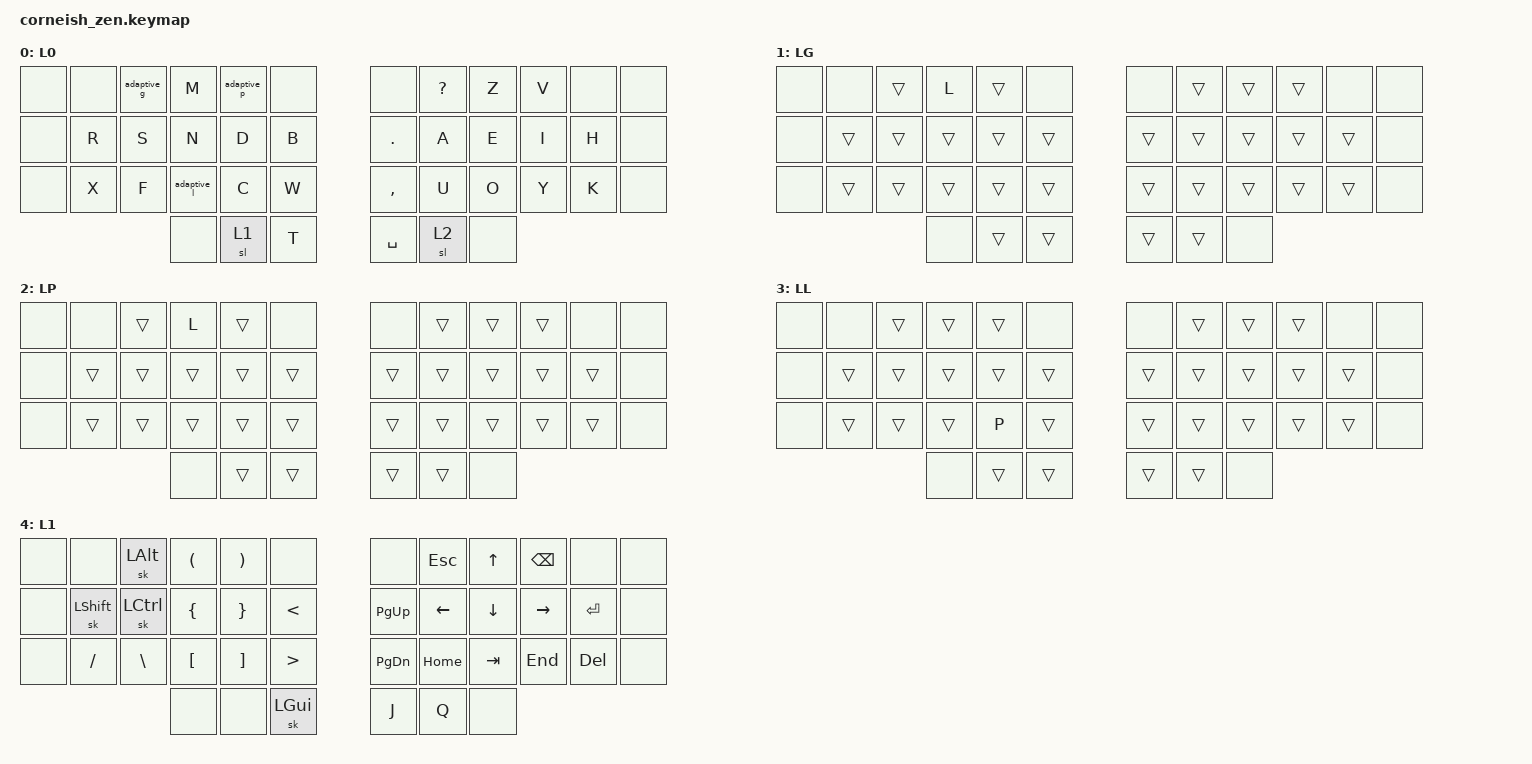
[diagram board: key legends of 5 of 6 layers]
#include <behaviors.dtsi>
#include <dt-bindings/zmk/keys.h>
#include <dt-bindings/zmk/bt.h>
#include <dt-bindings/zmk/outputs.h>

#define U_PST &kp LC(V)
#define U_CPY &kp LC(C)
#define U_CUT &kp LC(X)
#define U_UND &kp LC(Z)
#define U_RDO &kp LC(LS(Z))
#define U_MIC &kp LG(LA(K))

#define L0 0
#define LG 1
#define LP 2
#define LL 3
#define L1 4
#define L2 5

#define HT_1              &http   F1      NUM_1
#define HT_2              &http   F2      NUM_2
#define HT_3              &http   F3      NUM_3
#define HT_4              &http   F4      NUM_4
#define HT_5              &http   F5      NUM_5
#define HT_6              &http   F6      NUM_6
#define HT_7              &http   F7      NUM_7
#define HT_8              &http   F8      NUM_8
#define HT_9              &http   F9      NUM_9
#define HT_10             &http   F10     NUM_0
#define HT_11_AST         &http   F11     KP_ASTERISK
#define HT_12_CUT         &http   F12     LC(X)
#define HT_HASH_AT_SIGN   &http   HASH    AT_SIGN
#define HT_GRAVE_SQT      &http   GRAVE   SQT
#define HT_PERCENT_DOLLAR &http   PERCENT DOLLAR
#define HT_CARET_TILDE    &http   CARET   TILDE

/*
                                L0

      ╭─────┬─────┬─────╮                  ╭─────┬─────┬─────╮
      │  G  │  M  │  P  │                  │  ?  │  Z  │  V  │
╭─────┼─────┼─────┼─────┼─────╮      ╭─────┼─────┼─────┼─────┼─────╮
│  R  │  S  │  N  │  D  │  B  │      │  .  │  A  │  E  │  I  │  H  │
├─────┼─────┼─────┼─────┼─────┤      ├[btc]┼─────┼─────┼─────┼─────┤
│  X  │  F  │  L  │  C  │  W  │      │  ,  │  U  |  O  |  Y  │  K  │
╰─────┴─────┴─────┼─────┼─────┤      ├─────┼─────┼─────┴─────┴─────╯
                  │  L1 │  T  │      │ spc │  L2 │
                  ╰─────┴─────╯      ╰─────┴─────╯

                                 L1

      ╭─────┬─────┬─────╮                  ╭─────┬─────┬─────╮
      │ cut │ cpy │ pst │                  │ esc │  ↑  │ bspc│
╭─────┼─────┼─────┼─────┼─────╮      ╭─────┼─────┼─────┼─────┼─────╮
│ shft│ ctrl│ alt │ gui │ ~ ` │      │ pgup│  ←  │  ↓  │  →  │ ret │
├─────┼─────┼─────┼─────┼─────┤      ├─────┼─────┼─────┼─────┼─────┤
│ / \ │ [ ] │ { } │ ( ) │ < > │      │ pgdn│ home│ tab │ end │ del │
╰─────┴─────┴─────┼─────┼─────┤      ├─────┼─────┼─────┴─────┴─────╯
                  │  L1 │     │      │  J  │  Q  │
                  ╰─────┴─────╯      ╰─────┴─────╯

                                 L2
      ╭─────┬─────┬─────╮                  ╭─────┬─────┬─────╮
 {F10}│{F}7 │{F}8 │{F}9 │                  │  !  │  &  │  |  │
╭──┴──┼─────┼─────┼─────┼─────╮      ╭─────┼─────┼─────┼─────┼─────╮
│  0  │{F}4 │{F}5 │{F}6 │  +  │      │  '  │  "  │  =  │  @  │  ;  │
├─────┼─────┼─────┼─────┼─────┤      ├─────┼─────┼─────┼─────┼─────┤
│  *  │{F}1 │{F}2 │{F}3 │  -  ├{F12} │  ^  │  #  │  $  │  %  │  _  │
╰──┬──┴─────┴─────┼─────┼─────┤      ├─────┼─────┼─────┴─────┴─────╯
 {F11}            │ und │ rdo │      │     │  L2 │
                  ╰─────┴─────╯      ╰─────┴─────╯
*/
/ {
        keymap {
                compatible = "zmk,keymap";
                     L0 {
                        label = "L0";
                        bindings = <
/*                                       ╭───────────────────┬───────────────────┬───────────────────╮                                              ╭───────────────────┬───────────────────┬───────────────────╮                                      */
     &none                  &none              &adaptive_g           &kp M             &adaptive_p          &none                       &none           &kp QUESTION           &kp Z                &kp V               &none            &none
/*                   ╭───────────────────┼───────────────────┼───────────────────┼───────────────────┼───────────────────╮      ╭───────────────────┼───────────────────┼───────────────────┼───────────────────┼───────────────────╮                  */
     &none                  &kp R              &kp S                 &kp N                &kp D             &kp B                      &kp DOT             &kp A               &kp E                &kp I               &kp H            &none
/*                   ├───────────────────┼───────────────────┼───────────────────┼───────────────────┼───────────────────┤      ├───────────────────┼───────────────────┼───────────────────┼───────────────────┼───────────────────┤                  */
     &none                  &kp X              &kp F              &adaptive_l             &kp C             &kp W                     &kp COMMA            &kp U               &kp O                &kp Y               &kp K            &none
/*                   ╰───────────────────┴───────────────────┴───────────────────┼───────────────────┼───────────────────┤      ├───────────────────┼───────────────────┼───────────────────┴───────────────────┴───────────────────╯                  */
                                                                    &none                &sl L1             &kp T                     &kp SPACE            &sl L2           &none
/*                                                                               ╰───────────────────┴───────────────────╯      ╰───────────────────┴───────────────────╯                                                                              */
                             >;
                     };
                     LG {
                        label = "LG";
                        bindings = <
/*                                       ╭───────────────────┬───────────────────┬───────────────────╮                                              ╭───────────────────┬───────────────────┬───────────────────╮                                      */
     &none                  &none               &trans               &kp L              &trans              &none                      &none               &trans               &trans              &trans             &none             &none
/*                   ╭───────────────────┼───────────────────┼───────────────────┼───────────────────┼───────────────────╮      ╭───────────────────┼───────────────────┼───────────────────┼───────────────────┼───────────────────╮                  */
     &none                  &trans              &trans              &trans              &trans              &trans                     &trans              &trans               &trans              &trans             &trans            &none
/*                   ├───────────────────┼───────────────────┼───────────────────┼───────────────────┼───────────────────┤      ├───────────────────┼───────────────────┼───────────────────┼───────────────────┼───────────────────┤                  */
     &none                  &trans              &trans              &trans              &trans              &trans                     &trans              &trans               &trans              &trans             &trans            &none
/*                   ╰───────────────────┴───────────────────┴───────────────────┼───────────────────┼───────────────────┤      ├───────────────────┼───────────────────┼───────────────────┴───────────────────┴───────────────────╯                  */
                                                                    &none               &trans              &trans                     &trans              &trans               &none
/*                                                                               ╰───────────────────┴───────────────────╯      ╰───────────────────┴───────────────────╯                                                                              */
                             >;
                     };
                     LP {
                        label = "LP";
                        bindings = <
/*                                       ╭───────────────────┬───────────────────┬───────────────────╮                                              ╭───────────────────┬───────────────────┬───────────────────╮                                      */
     &none                  &none               &trans               &kp L              &trans              &none                      &none               &trans               &trans              &trans             &none             &none
/*                   ╭───────────────────┼───────────────────┼───────────────────┼───────────────────┼───────────────────╮      ╭───────────────────┼───────────────────┼───────────────────┼───────────────────┼───────────────────╮                  */
     &none                  &trans              &trans              &trans              &trans              &trans                     &trans              &trans               &trans              &trans             &trans            &none
/*                   ├───────────────────┼───────────────────┼───────────────────┼───────────────────┼───────────────────┤      ├───────────────────┼───────────────────┼───────────────────┼───────────────────┼───────────────────┤                  */
     &none                  &trans              &trans              &trans              &trans              &trans                     &trans              &trans               &trans              &trans             &trans            &none
/*                   ╰───────────────────┴───────────────────┴───────────────────┼───────────────────┼───────────────────┤      ├───────────────────┼───────────────────┼───────────────────┴───────────────────┴───────────────────╯                  */
                                                                    &none               &trans              &trans                     &trans              &trans               &none
/*                                                                               ╰───────────────────┴───────────────────╯      ╰───────────────────┴───────────────────╯                                                                              */
                             >;
                     };
                     LL {
                        label = "LL";
                        bindings = <
/*                                       ╭───────────────────┬───────────────────┬───────────────────╮                                              ╭───────────────────┬───────────────────┬───────────────────╮                                      */
     &none                  &none               &trans              &trans              &trans              &none                      &none               &trans               &trans              &trans             &none             &none
/*                   ╭───────────────────┼───────────────────┼───────────────────┼───────────────────┼───────────────────╮      ╭───────────────────┼───────────────────┼───────────────────┼───────────────────┼───────────────────╮                  */
     &none                  &trans              &trans              &trans              &trans              &trans                     &trans              &trans               &trans              &trans             &trans            &none
/*                   ├───────────────────┼───────────────────┼───────────────────┼───────────────────┼───────────────────┤      ├───────────────────┼───────────────────┼───────────────────┼───────────────────┼───────────────────┤                  */
     &none                  &trans              &trans              &trans              &kp P               &trans                     &trans              &trans               &trans              &trans             &trans            &none
/*                   ╰───────────────────┴───────────────────┴───────────────────┼───────────────────┼───────────────────┤      ├───────────────────┼───────────────────┼───────────────────┴───────────────────┴───────────────────╯                  */
                                                                    &none               &trans              &trans                     &trans              &trans               &none
/*                                                                               ╰───────────────────┴───────────────────╯      ╰───────────────────┴───────────────────╯                                                                              */
                             >;
                     };
                     L1 {
                             label = "L1";
                             bindings = <
/*                                       ╭───────────────────┬───────────────────┬───────────────────╮                                              ╭───────────────────┬───────────────────┬───────────────────╮                                      */
     &none                   &none             &sk LALT            &kp LPAR            &kp RPAR            &none                      &none               &kp ESC             &kp UP              &kp BSPC              &none             &none
/*                   ╭───────────────────┼───────────────────┼───────────────────┼───────────────────┼───────────────────╮      ╭───────────────────┼───────────────────┼───────────────────┼───────────────────┼───────────────────╮                  */
     &none                 &sk LSHFT           &sk LCTRL           &kp LBRC            &kp RBRC            &kp LT                     &kp PG_UP           &kp LEFT            &kp DOWN             &kp RIGHT           &kp ENTER          &none
/*                   ├───────────────────┼───────────────────┼───────────────────┼───────────────────┼───────────────────┤      ├───────────────────┼───────────────────┼───────────────────┼───────────────────┼───────────────────┤                  */
     &none                 &kp SLASH         &kp BACKSLASH         &kp LBKT            &kp RBKT            &kp GT                     &kp PG_DN           &kp HOME            &kp TAB              &kp END             &kp DEL            &none
/*                   ╰───────────────────┴───────────────────┴───────────────────┼───────────────────┼───────────────────┤      ├───────────────────┼───────────────────┼───────────────────┴───────────────────┴───────────────────╯                  */
                                                                  &none                &none               &sk LGUI                   &kp J               &kp Q              &none
/*                                                                               ╰───────────────────┴───────────────────╯      ╰───────────────────┴───────────────────╯                                                                              */
                             >;
                     };
                     L2 {
                             label = "L2";
                             bindings = <
/*                                       ╭───────────────────┬───────────────────┬───────────────────╮                                              ╭───────────────────┬───────────────────┬───────────────────╮                                      */
     &none                   &none               HT_7                HT_8                HT_9              &none                       &none            &kp EXCLAMATION     &kp AMPERSAND         &kp PIPE             &none              &none
/*                   ╭───────────────────┼───────────────────┼───────────────────┼───────────────────┼───────────────────╮      ╭───────────────────┼───────────────────┼───────────────────┼───────────────────┼───────────────────╮                  */
     &none                   HT_10               HT_4                HT_5                HT_6               U_CPY                   HT_GRAVE_SQT           &kp DQT            &kp EQUAL           &kp KP_PLUS          &kp SEMI           &none
/*                   ├───────────────────┼───────────────────┼───────────────────┼───────────────────┼───────────────────┤      ├───────────────────┼───────────────────┼───────────────────┼───────────────────┼───────────────────┤                  */
     &none                   HT_11_AST           HT_1                HT_2                HT_3             HT_12_CUT                HT_HASH_AT_SIGN    HT_PERCENT_DOLLAR    HT_CARET_TILDE         &kp MINUS         &kp UNDERSCORE        &none
/*                   ╰───────────────────┴───────────────────┴───────────────────┼───────────────────┼───────────────────┤      ├───────────────────┼───────────────────┼───────────────────┴───────────────────┴───────────────────╯                  */
                                                                   &none                U_UND               U_PST                       U_RDO              &none
/*                                                                               ╰───────────────────┴───────────────────╯      ╰───────────────────┴───────────────────╯                                                                              */
                             >;
                     };
        };
      macros {
        ZMK_MACRO(adaptive_g,
            wait-ms = <30>;
            tap-ms = <30>;
            bindings = <&kp G &sl LG>;
        )
        ZMK_MACRO(adaptive_p,
            wait-ms = <30>;
            tap-ms = <30>;
            bindings = <&kp P &sl LP>;
        )
        ZMK_MACRO(adaptive_l,
            wait-ms = <30>;
            tap-ms = <30>;
            bindings = <&kp L &sl LL>;
        )
     };
    behaviors {
        http: hold_tap_tap_preferred {
            compatible = "zmk,behavior-hold-tap";
            label = "hold tap";
            #binding-cells = <2>;
            tapping_term_ms = <250>;
            quick_tap_ms = <0>;
            flavor = "tap-preferred";
            bindings = <&kp>, <&kp>;
        };
    };
/*
      ╭─────┬─────┬─────╮                  ╭─────┬─────┬─────╮
      │  2  │  3  │  4  │                  │  7  │  8  │  9  │
╭─────┼─────┼─────┼─────┼─────╮      ╭─────┼─────┼─────┼─────┼─────╮
│  13 │  14 │  15 │  16 │  17 │      │  18 │  19 │  20 │  21 │  22 │
├─────┼─────┼─────┼─────┼─────┤      ├─────┼─────┼─────┼─────┼─────┤
│  25 │  26 │  27 │  28 │  29 │      │  30 │  31 |  32 |  33 │  34 │
╰─────┴─────┴─────┼─────┼─────┤      ├─────┼─────┼─────┴─────┴─────╯
                  │  37 │  38 │      │  39 │  40 │
                  ╰─────┴─────╯      ╰─────┴─────╯
*/
    combos {
        compatible = "zmk,combos";
        combo_bt {
               timeout-ms = <60>;
               key-positions = <18 30>;
               bindings = <&bt BT_CLR>;
               layers = <0>;
        };
    };
};
